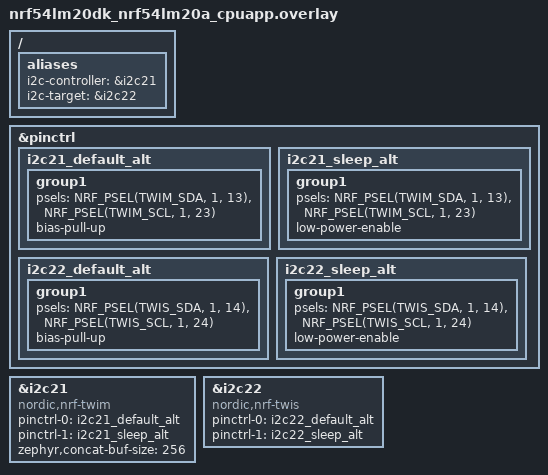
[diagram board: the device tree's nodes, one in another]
/*
 * Copyright (c) 2026 Nordic Semiconductor ASA
 *
 * SPDX-License-Identifier: LicenseRef-Nordic-5-Clause
 */

/*
 * SDA = P1.13 and P1.14
 * SCL = P1.23 and P1.24
 */

/ {
	aliases {
		i2c-controller = &i2c21;
		i2c-target = &i2c22;
	};
};

&pinctrl {
	i2c21_default_alt: i2c21_default_alt {
		group1 {
			psels = <NRF_PSEL(TWIM_SDA, 1, 13)>,
				<NRF_PSEL(TWIM_SCL, 1, 23)>;
			bias-pull-up;
		};
	};

	i2c21_sleep_alt: i2c21_sleep_alt {
		group1 {
			psels = <NRF_PSEL(TWIM_SDA, 1, 13)>,
				<NRF_PSEL(TWIM_SCL, 1, 23)>;
			low-power-enable;
		};
	};

	i2c22_default_alt: i2c22_default_alt {
		group1 {
			psels = <NRF_PSEL(TWIS_SDA, 1, 14)>,
				<NRF_PSEL(TWIS_SCL, 1, 24)>;
			bias-pull-up;
		};
	};

	i2c22_sleep_alt: i2c22_sleep_alt {
		group1 {
			psels = <NRF_PSEL(TWIS_SDA, 1, 14)>,
				<NRF_PSEL(TWIS_SCL, 1, 24)>;
			low-power-enable;
		};
	};
};

&i2c21 {
	compatible = "nordic,nrf-twim";
	pinctrl-0 = <&i2c21_default_alt>;
	pinctrl-1 = <&i2c21_sleep_alt>;
	pinctrl-names = "default", "sleep";
	zephyr,concat-buf-size = <256>;
	status = "okay";
};

&i2c22 {
	compatible = "nordic,nrf-twis";
	pinctrl-0 = <&i2c22_default_alt>;
	pinctrl-1 = <&i2c22_sleep_alt>;
	pinctrl-names = "default", "sleep";
	status = "okay";
};
